# lpcb register map
Vendor: Texas Instruments
Peripheral module from a debugger description file (folder sc4e129bnczad).
Registers are 32-bit, read-write, no defined reset value unless marked. A register's access mark holds for its fields unless they carry their own. Offsets are as the file gives them; lines under a group give offsets from that group; [hi:lo] are bit positions; {n}, {i} and the like mark numbered series; 'fields as' and 'values as' point back to an identical list; <NAME> marks a mode.

## LPCB0 — LPCB register offsets
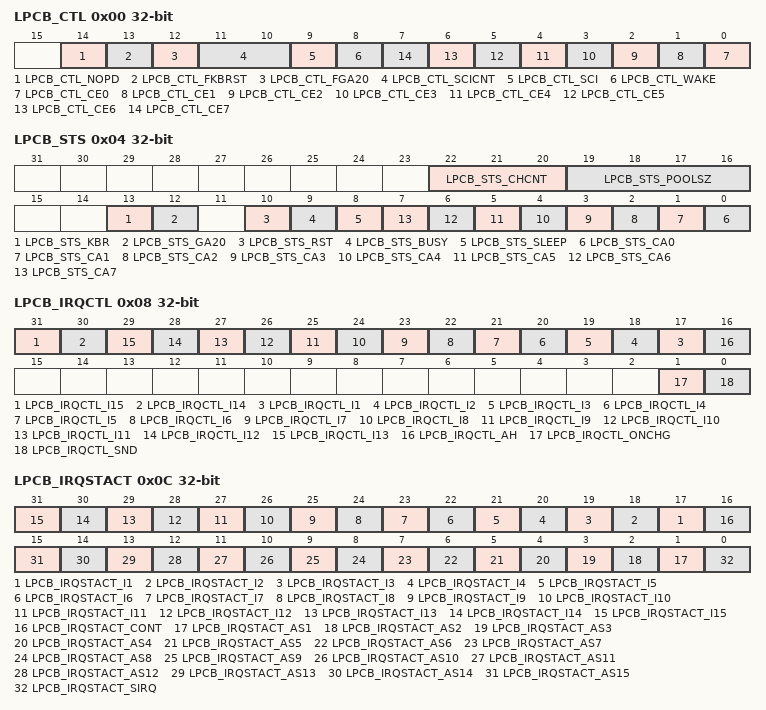
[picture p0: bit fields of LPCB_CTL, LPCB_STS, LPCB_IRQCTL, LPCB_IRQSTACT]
0x00 LPCB_CTL — LPCB Control
  [14] LPCB_CTL_NOPD — No Power Down Mode
  [13] LPCB_CTL_FKBRST — Fast Keyboard Reset Channel 0 Enable
  [12] LPCB_CTL_FGA20 — Fast Gate A-20 Channel 0 Enable
  [11:10] LPCB_CTL_SCICNT — LPC0SCI Pulse Length
    0=1-clock pulse; 1=2-clock pulse; 2=4-clock pulse; 3=8-clock pulse
  [9] LPCB_CTL_SCI — Start LPC0SCI Pulse
  [8] LPCB_CTL_WAKE — Wake or Keep Awake the LPC Bus
  [n] LPCB_CTL_CE{n} (n=0..7) — Enable Channel {n}
0x04 LPCB_STS ro — LPCB Status
  [22:20] LPCB_STS_CHCNT — Number of Channels
  [19:16] LPCB_STS_POOLSZ — Register Pool Size
    1=256 bytes; 2=512 bytes; 3=768 bytes; 4=1024 bytes; 5=1280 bytes; 6=1536 bytes; 7=1792 bytes; 8=2048 bytes
  [13] LPCB_STS_KBR — LPC Keyboard Reset Status
  [12] LPCB_STS_GA20 — Gate A20 Status
  [10] LPCB_STS_RST — LPC Bus is in Reset
  [9] LPCB_STS_BUSY — LPC is Busy
  [8] LPCB_STS_SLEEP — Sleep Mode
  [n] LPCB_STS_CA{n} (n=0..7) — Channel {n} Active
0x08 LPCB_IRQCTL — LPCB IRQ Control
  [31] LPCB_IRQCTL_I15 — Pulsed IRQ15 State
  [30] LPCB_IRQCTL_I14 — Pulsed IRQ14 State
  [n+16] LPCB_IRQCTL_I{n} (n=1..13) — Pulsed IIRQ{n} State
  [16] LPCB_IRQCTL_AH — Active High Control
  [1] LPCB_IRQCTL_ONCHG — Initiate on Change
  [0] LPCB_IRQCTL_SND — Initiate Immediately
0x0C LPCB_IRQSTACT — LPCB IRQ Status and Active State
  [n+16] LPCB_IRQSTACT_I{n} (n=1..15) — IRQ{n} State
  [16] LPCB_IRQSTACT_CONT — Continuous Mode Status
  [n] LPCB_IRQSTACT_AS{n} (n=1..15) — IRQ{n} Active State
  [0] LPCB_IRQSTACT_SIRQ — SERIRQ Transaction Frame Being Processed
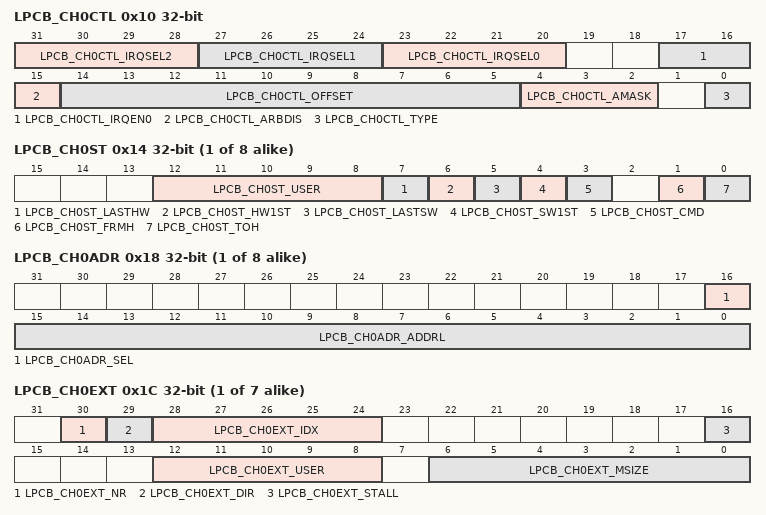
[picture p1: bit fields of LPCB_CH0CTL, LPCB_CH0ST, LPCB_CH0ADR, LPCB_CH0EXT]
0x10 LPCB_CH0CTL — LPCB Channel 0 Control
  [31:28] LPCB_CH0CTL_IRQSEL2 — IRQ Select 2
  [27:24] LPCB_CH0CTL_IRQSEL1 — IRQ Select 1
  [23:20] LPCB_CH0CTL_IRQSEL0 — IRQ Select 0
  [17:16] LPCB_CH0CTL_IRQEN0 — IRQ Enable 0
    0=LPCB_CH0CTL_IRQEN0_DIS (Trigger disabled); 1=LPCB_CH0CTL_IRQEN0_TRIG1 (Trigger 1); 2=LPCB_CH0CTL_IRQEN0_TRIG2 (Trigger 2); 3=LPCB_CH0CTL_IRQEN0_TRIG3 (Trigger 3)
  [15] LPCB_CH0CTL_ARBDIS — Arbitration Disabled
  [14:5] LPCB_CH0CTL_OFFSET — Base Offset in Register Pool
  [4:2] LPCB_CH0CTL_AMASK — Address Mask for Ranges
    0=4 bytes; 1=8 bytes; 2=16 bytes; 3=32 bytes; 4=64 bytes; 5=128 bytes; 6=256 bytes; 7=512 bytes
  [0] LPCB_CH0CTL_TYPE — Channel Type
{0x14+0x10*i} LPCB_CH{i}ST (i=0..7) — LPCB Channel {i} Status
  [12:8] LPCB_CH{i}ST_USER — User Data
  [7] LPCB_CH{i}ST_LASTHW — Last Host Write
  [6] LPCB_CH{i}ST_HW1ST — Host Wrote First
  [5] LPCB_CH{i}ST_LASTSW — Last Slave Write
  [4] LPCB_CH{i}ST_SW1ST — Slave Wrote First
  [3] LPCB_CH{i}ST_CMD — Command or Data
  [1] LPCB_CH{i}ST_FRMH — From-Host Transaction
  [0] LPCB_CH{i}ST_TOH — To-Host Transaction
{0x18+0x10*i} LPCB_CH{i}ADR (i=0..7) — LPCB Channel {i} Address
  [16] LPCB_CH{i}ADR_SEL — Upper Address Select
  [15:0] LPCB_CH{i}ADR_ADDRL — Lower Address Match
{0x1C+0x10*i} LPCB_CH{i}EXT (i=0..6) — LPCB Channel {i} Extension
  [30] LPCB_CH{i}EXT_NR — Not Ready Status
  [29] LPCB_CH{i}EXT_DIR — Mailbox Operation Direction
  [28:24] LPCB_CH{i}EXT_IDX — Mailbox Operation Index
  [16] LPCB_CH{i}EXT_STALL — Stall Mode Enable
  [12:8] LPCB_CH{i}EXT_USER — User Status
  [6:0] LPCB_CH{i}EXT_MSIZE — Mailbox Size
    0=LPCB_CH{i}EXT_MSIZE_FULL (Mailbox range is full size. MSIZE does not change mailbox range)
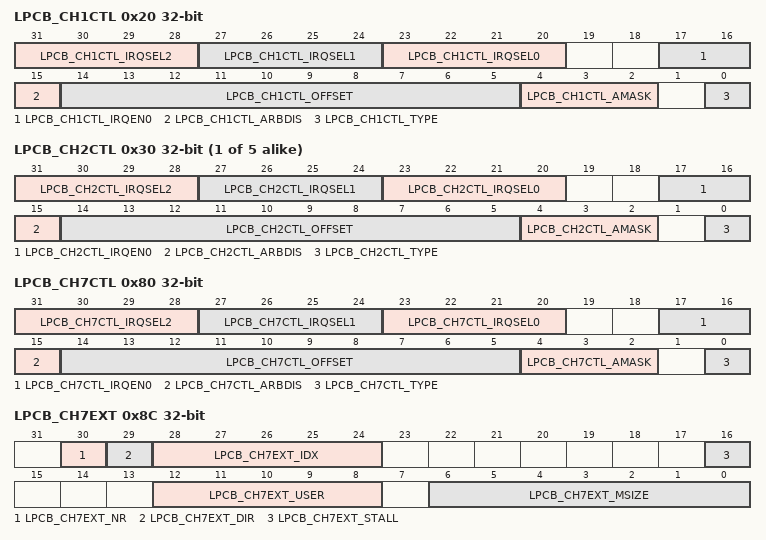
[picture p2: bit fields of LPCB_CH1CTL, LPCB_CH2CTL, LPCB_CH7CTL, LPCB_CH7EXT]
0x20 LPCB_CH1CTL — LPCB Channel 1 Control
  [31:28] LPCB_CH1CTL_IRQSEL2 — IRQ Select 2
  [27:24] LPCB_CH1CTL_IRQSEL1 — IRQ Select 1
  [23:20] LPCB_CH1CTL_IRQSEL0 — IRQ Select 0
  [17:16] LPCB_CH1CTL_IRQEN0 — IRQ Enable 0
    0=LPCB_CH1CTL_IRQEN0_DIS (Trigger disabled); 1=LPCB_CH1CTL_IRQEN0_TRIG1 (Trigger 1); 2=LPCB_CH1CTL_IRQEN0_TRGI2 (Trigger 2); 3=LPCB_CH1CTL_IRQEN0_TRGI3 (Trigger 3)
  [15] LPCB_CH1CTL_ARBDIS — Arbitration Disabled
  [14:5] LPCB_CH1CTL_OFFSET — Base Offset in Register Pool
  [4:2] LPCB_CH1CTL_AMASK — Address Mask for Ranges
    values as LPCB_CH0CTL.LPCB_CH0CTL_AMASK
  [0] LPCB_CH1CTL_TYPE — Channel Type
{0x10+0x10*i} LPCB_CH{i}CTL (i=2..6) — LPCB Channel {i} Control
  [31:28] LPCB_CH{i}CTL_IRQSEL2 — IRQ Select 2
  [27:24] LPCB_CH{i}CTL_IRQSEL1 — IRQ Select 1
  [23:20] LPCB_CH{i}CTL_IRQSEL0 — IRQ Select 0
  [17:16] LPCB_CH{i}CTL_IRQEN0 — IRQ Enable 0
    0=LPCB_CH{i}CTL_IRQEN0_DIS (Trigger disabled); 1=LPCB_CH{i}CTL_IRQEN0_TRIG1 (Trigger 1); 2=LPCB_CH{i}CTL_IRQEN0_TRIG2 (Trigger 2); 3=LPCB_CH{i}CTL_IRQEN0_TRIG3 (Trigger 3)
  [15] LPCB_CH{i}CTL_ARBDIS — Arbitration Disabled
  [14:5] LPCB_CH{i}CTL_OFFSET — Base Offset in Register Pool
  [4:2] LPCB_CH{i}CTL_AMASK — Address Mask for Ranges
    values as LPCB_CH0CTL.LPCB_CH0CTL_AMASK
  [0] LPCB_CH{i}CTL_TYPE — Channel Type
0x80 LPCB_CH7CTL — LPCB Channel 7 Control
  [31:28] LPCB_CH7CTL_IRQSEL2 — IRQ Select 2
  [27:24] LPCB_CH7CTL_IRQSEL1 — IRQ Select 1
  [23:20] LPCB_CH7CTL_IRQSEL0 — IRQ Select 0
  [17:16] LPCB_CH7CTL_IRQEN0 — IRQ Enable 0
    0=LPCB_CH7CTL_IRQEN0_AUTO (Trigger disabled); 1=LPCB_CH7CTL_IRQEN0_MST (Trigger 1); 2=LPCB_CH7CTL_IRQEN0_SLV (Trigger 2); 3=LPCB_CH7CTL_IRQEN0_TRIG3 (Trigger 3)
  [15] LPCB_CH7CTL_ARBDIS — Arbitration Disabled
  [14:5] LPCB_CH7CTL_OFFSET — Base Offset in Register Pool
  [4:2] LPCB_CH7CTL_AMASK — Address Mask for Ranges
    values as LPCB_CH0CTL.LPCB_CH0CTL_AMASK
  [0] LPCB_CH7CTL_TYPE — Channel Type
0x8C LPCB_CH7EXT — LPCB Channel 7 Extension
  [30] LPCB_CH7EXT_NR — Not Ready Status
  [29] LPCB_CH7EXT_DIR — Mailbox Operation Direction
  [28:24] LPCB_CH7EXT_IDX — Mailbox Operation Index
  [16] LPCB_CH7EXT_STALL — Stall Mode Enable
  [12:8] LPCB_CH7EXT_USER — User Status
  [6:0] LPCB_CH7EXT_MSIZE — Mailbox Size
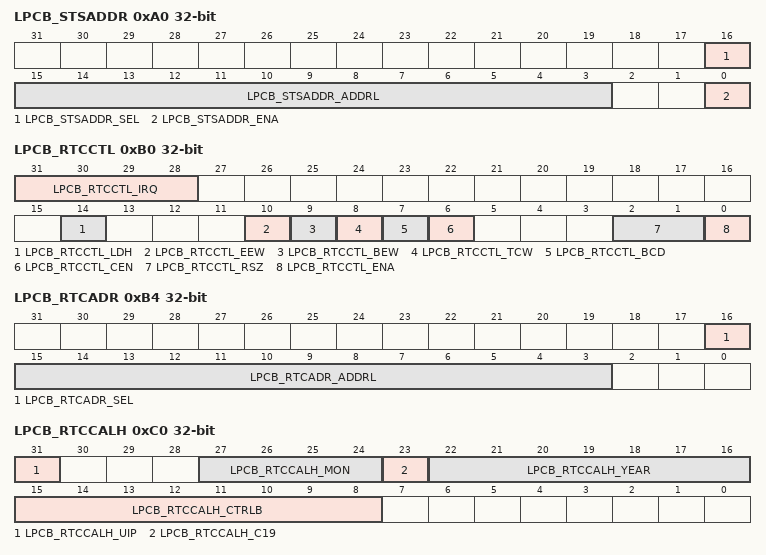
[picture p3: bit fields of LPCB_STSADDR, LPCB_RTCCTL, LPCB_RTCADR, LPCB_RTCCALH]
0xA0 LPCB_STSADDR — LPCB Status Block Address
  [16] LPCB_STSADDR_SEL — Upper Address Selector
  [15:3] LPCB_STSADDR_ADDRL — Lower Address Match
  [0] LPCB_STSADDR_ENA — Enable Status Block
0xB0 LPCB_RTCCTL — LPCB RTC Control
  [31:28] LPCB_RTCCTL_IRQ — IRQ Enable
  [14] LPCB_RTCCTL_LDH — Load Data
  [10] LPCB_RTCCTL_EEW — Extended Memory Write
  [9] LPCB_RTCCTL_BEW — Base Memory Write
  [8] LPCB_RTCCTL_TCW — TOD/Calendar Write
  [7] LPCB_RTCCTL_BCD — BCD Status
  [6] LPCB_RTCCTL_CEN — Century Enable
  [2:1] LPCB_RTCCTL_RSZ — RTC RAM Size
    0=64 bytes (50); 1=128 bytes (114); 2=256 bytes (242); 3=512 bytes (498)
  [0] LPCB_RTCCTL_ENA — RTC TOD/Calendar Enable
0xB4 LPCB_RTCADR — LPCB RTC Address
  [16] LPCB_RTCADR_SEL — Upper Address Selector
  [15:3] LPCB_RTCADR_ADDRL — Lower Address Match
0xC0 LPCB_RTCCALH — LPCB RTC Calendar High
  [31] LPCB_RTCCALH_UIP — Update in Progress
  [27:24] LPCB_RTCCALH_MON — Month Value
  [23] LPCB_RTCCALH_C19 — Century Value
  [22:16] LPCB_RTCCALH_YEAR — Year Value
  [15:8] LPCB_RTCCALH_CTRLB — CTRLB Value
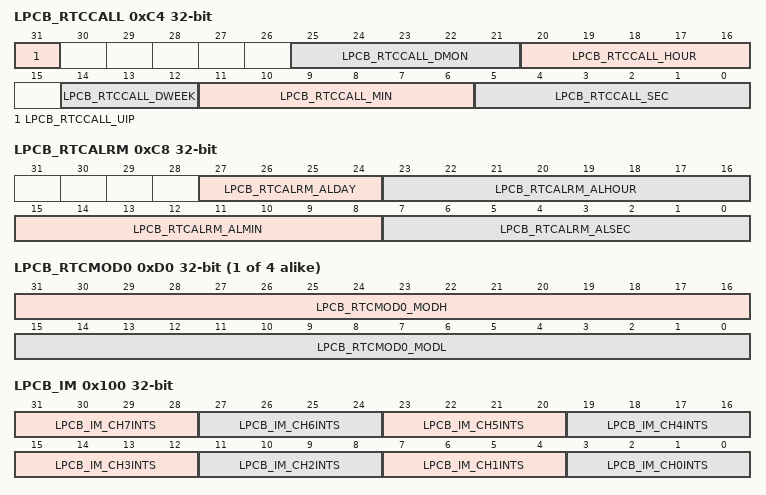
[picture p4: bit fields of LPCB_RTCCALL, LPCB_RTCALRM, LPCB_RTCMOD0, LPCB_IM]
0xC4 LPCB_RTCCALL — LPCB RTC Calendar Low
  [31] LPCB_RTCCALL_UIP — Update in Progress
  [25:21] LPCB_RTCCALL_DMON — Day-of-Month Value
  [20:16] LPCB_RTCCALL_HOUR — Hour Value
  [14:12] LPCB_RTCCALL_DWEEK — Day-of-Week Value
  [11:6] LPCB_RTCCALL_MIN — Minute Value
  [5:0] LPCB_RTCCALL_SEC — Seconds Value
0xC8 LPCB_RTCALRM — LPCB RTC Alarm
  [27:24] LPCB_RTCALRM_ALDAY — Hour Alarm
  [23:16] LPCB_RTCALRM_ALHOUR — Hour Alarm
  [15:8] LPCB_RTCALRM_ALMIN — Minute Alarm
  [7:0] LPCB_RTCALRM_ALSEC — Seconds Alarm
{0xD0+4i} LPCB_RTCMOD{i} (i=0..3) — LPCB RTC Modify {i} Register
  [31:16] LPCB_RTCMOD{i}_MODH — RTC Pool Upper Modification Status
  [15:0] LPCB_RTCMOD{i}_MODL — RTC Pool Lower Memory Modification Status
0x100 LPCB_IM — LPCB Interrupt Mask
  [31:28] LPCB_IM_CH7INTS — Channel 7 Interrupt Mask
    0=LPCB_IM_CH7INTS__0 (Stall); 1=LPCB_IM_CH7INTS__1 (Stall); 2=LPCB_IM_CH7INTS__2 (MB); 3=LPCB_IM_CH7INTS__3 (MB)
  [4n+3:4n] LPCB_IM_CH{n}INTS (n=0..6) — Channel {n} Interrupt Mask
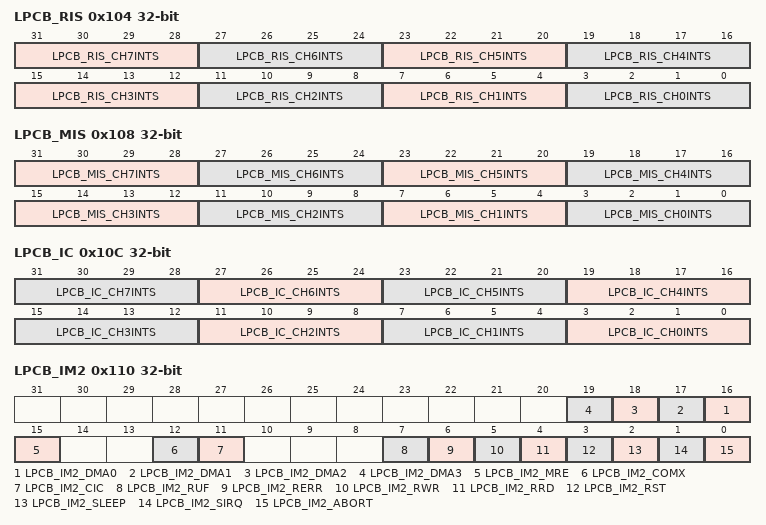
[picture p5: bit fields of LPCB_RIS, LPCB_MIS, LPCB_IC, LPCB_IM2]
0x104 LPCB_RIS ro — LPCB Raw Interrupt Status
  [31:28] LPCB_RIS_CH7INTS — Channel 7 Raw Interrupt Status
    0=LPCB_RIS_CH7INTS__0 (Stall); 1=LPCB_RIS_CH7INTS__1 (Stall); 2=LPCB_RIS_CH7INTS__2 (MB); 3=LPCB_RIS_CH7INTS__3 (MB)
  [4n+3:4n] LPCB_RIS_CH{n}INTS (n=0..6) — Channel {n} Raw Interrupt Status
0x108 LPCB_MIS ro — LPCB Masked Interrupt Status
  [31:28] LPCB_MIS_CH7INTS — Channel 7 Masked Interrupt Status
    0=LPCB_MIS_CH7INTS__0 (Stall); 1=LPCB_MIS_CH7INTS__1 (Stall); 2=LPCB_MIS_CH7INTS__2 (MB); 3=LPCB_MIS_CH7INTS__3 (MB)
  [4n+3:4n] LPCB_MIS_CH{n}INTS (n=0..6) — Channel {n} Masked Interrupt Status
0x10C LPCB_IC wo — LPCB Interrupt Clear
  [4n+3:4n] LPCB_IC_CH{n}INTS (n=0..7) — Channel {n} Interrupt Clear
0x110 LPCB_IM2 — LPCB Interrupt Mask 2
  [n+16] LPCB_IM2_DMA{n} (n=0..3) — DMA Done Channel {n} Interrupt Mask
  [15] LPCB_IM2_MRE — Memory Pool Retention Interrupt Mask
  [12] LPCB_IM2_COMX — COMx Interrupt Mask
  [11] LPCB_IM2_CIC — COMxy Intercept Interrupt Mask
  [7] LPCB_IM2_RUF — RTC Update Finish Interrupt Mask
  [6] LPCB_IM2_RERR — RTC Error Interrupt Mask
  [5] LPCB_IM2_RWR — RTC Write Interrupt Mask
  [4] LPCB_IM2_RRD — RTC Read Interrupt Mask
  [3] LPCB_IM2_RST — LPC Reset Interrupt Mask
  [2] LPCB_IM2_SLEEP — LPC Sleep Interrupt Mask
  [1] LPCB_IM2_SIRQ — SERIRQ Interrupt Mask
  [0] LPCB_IM2_ABORT — Abort Interrupt Mask
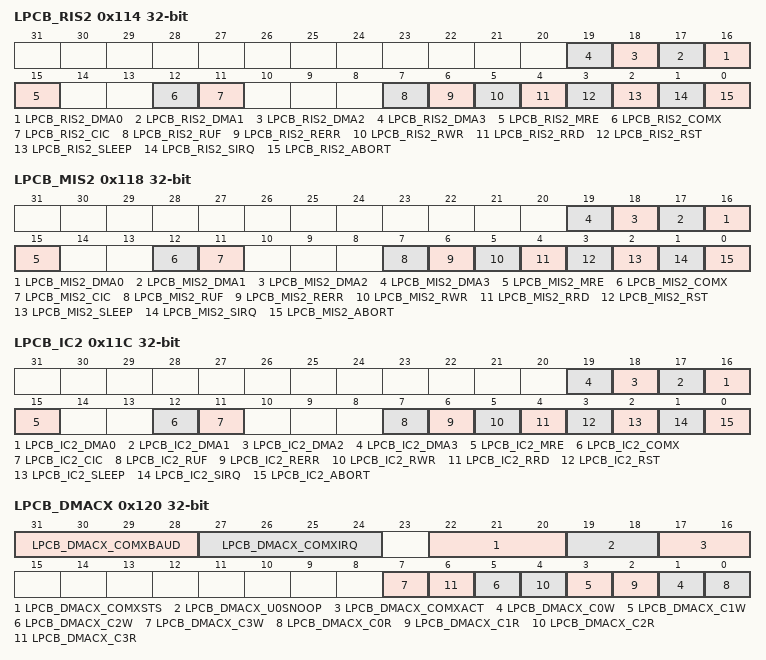
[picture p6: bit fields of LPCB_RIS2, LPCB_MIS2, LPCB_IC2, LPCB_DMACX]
0x114 LPCB_RIS2 — LPCB Raw Interrupt Status 2
  [n+16] LPCB_RIS2_DMA{n} (n=0..3) — DMA Done Channel {n} Raw Interrupt Status
  [15] LPCB_RIS2_MRE — Memory Pool Retention Raw Interrupt Status
  [12] LPCB_RIS2_COMX — COMx Raw Interrupt Status
  [11] LPCB_RIS2_CIC — COMxy Intercept Raw Interrupt Status
  [7] LPCB_RIS2_RUF — RTC Update Finish Raw Interrupt Status
  [6] LPCB_RIS2_RERR — RTC Error Raw Interrupt Status
  [5] LPCB_RIS2_RWR — RTC Write Raw Interrupt Status
  [4] LPCB_RIS2_RRD — RTC Read Raw Interrupt Status
  [3] LPCB_RIS2_RST — LPC Reset Raw Interrupt Status
  [2] LPCB_RIS2_SLEEP — LPC Sleep Raw Interrupt Status
  [1] LPCB_RIS2_SIRQ — SERIRQ Raw Interrupt Status
  [0] LPCB_RIS2_ABORT — Abort Raw Interrupt Status
0x118 LPCB_MIS2 — LPCB Masked Interrupt Status 2
  [n+16] LPCB_MIS2_DMA{n} (n=0..3) — DMA Done Channel {n} Masked Interrupt Status
  [15] LPCB_MIS2_MRE — Memory Pool Retention Masked Interrupt Status
  [12] LPCB_MIS2_COMX — COMx Masked Interrupt Status
  [11] LPCB_MIS2_CIC — COMxy Intercept Masked Interrupt Status
  [7] LPCB_MIS2_RUF — RTC Update Finish Masked Interrupt Status
  [6] LPCB_MIS2_RERR — RTC Error Masked Interrupt Status
  [5] LPCB_MIS2_RWR — RTC Write Masked Interrupt Status
  [4] LPCB_MIS2_RRD — RTC Read Masked Interrupt Status
  [3] LPCB_MIS2_RST — LPC Reset Masked Interrupt Status
  [2] LPCB_MIS2_SLEEP — LPC Sleep Masked Interrupt Status
  [1] LPCB_MIS2_SIRQ — SERIRQ Masked Interrupt Status
  [0] LPCB_MIS2_ABORT — Abort Masked Interrupt Status
0x11C LPCB_IC2 — LPCB Interrupt Clear 2
  [n+16] LPCB_IC2_DMA{n} (n=0..3) — Channel {n} DMA Done Interrupt Clear
  [15] LPCB_IC2_MRE — Memory Pool Retention Interrupt Clear
  [12] LPCB_IC2_COMX — COMx Interrupt Clear
  [11] LPCB_IC2_CIC — COMxy Intercept Mode Interrupt Clear
  [7] LPCB_IC2_RUF — RTC Update Finish Interrupt Clear
  [6] LPCB_IC2_RERR — RTC Error Interrupt Clear
  [5] LPCB_IC2_RWR — RTC Write Interrupt Clear
  [4] LPCB_IC2_RRD — RTC Read Interrupt Clear
  [3] LPCB_IC2_RST — LPC Reset Interrupt Clear
  [2] LPCB_IC2_SLEEP — LPC Sleep Interrupt Clear
  [1] LPCB_IC2_SIRQ — SERIRQ Interrupt Clear
  [0] LPCB_IC2_ABORT — Abort Interrupt Clear
0x120 LPCB_DMACX — LPCB DMA and COMx Control
  [31:28] LPCB_DMACX_COMXBAUD — COMx Baud Rate
    0=LPCB_DMACX_COMXBAUD_HOST (DLAB (host)); 1=9,600; 2=19,200; 3=38,400; 4=56,000; 5=115,200; 6=230,400; 7=460,800; 8=921,600; 9=1,250,000; 10=1,500,000; 11=2,500,000
  [27:24] LPCB_DMACX_COMXIRQ — COMx IRQ
  [22:20] LPCB_DMACX_COMXSTS — COMx Status
    0=LPCB_DMACX_COMXSTS_TOHOST (To-host reads have occurred); 1=LPCB_DMACX_COMXSTS_FROMHOST (From-host writes have occurred); 2=LPCB_DMACX_COMXSTS_ERROR (UART errors have occurred)
  [19:18] LPCB_DMACX_U0SNOOP — UART0 Snoop Enable
    0=LPCB_DMACX_U0SNOOP_NOSNOOP (No snoop); 1=LPCB_DMACX_U0SNOOP_SNPTX (Snoop 16550 TX); 2=LPCB_DMACX_U0SNOOP_SNPRX (Snoop 16550 RX)
  [17:16] LPCB_DMACX_COMXACT — COMx Configuration
    0=LPCB_DMACX_COMXACT_DIS (Disabled); 1=LPCB_DMACX_COMXACT_FLUSH (Ignore from-host bytes and continue to mark COMx TX status as empty. This tells the host the TX FIFO is not full, but just throws away data bytes from the host); 2=LPCB_DMACX_COMXACT_BLOCK (Blocked status. This marks the COMx TX status as full (FIFO full) holding the host off if it wants to send data bytes); 3=LPCB_DMACX_COMXACT_NORM (COMx model with 16550 UART as described in COMx channel support)
  [2n+1] LPCB_DMACX_C{n}W (n=0..3) — Channel {n} Write Control
  [2n] LPCB_DMACX_C{n}R (n=0..3) — Channel {n} Read Control
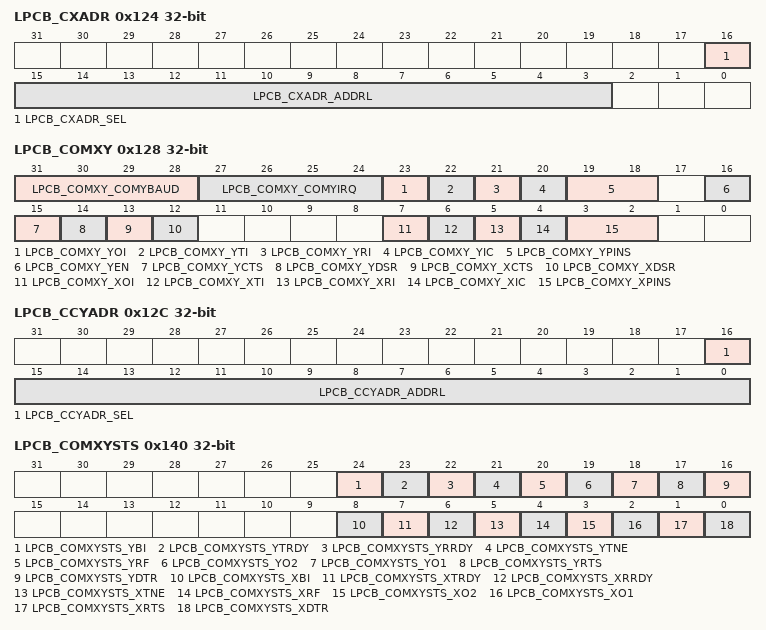
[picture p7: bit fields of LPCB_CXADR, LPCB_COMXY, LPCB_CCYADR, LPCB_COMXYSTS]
0x124 LPCB_CXADR — LPCB COMx Address
  [16] LPCB_CXADR_SEL — Upper Address Selector
  [15:3] LPCB_CXADR_ADDRL — Lower Address Match
0x128 LPCB_COMXY — LPCB COMx and COMy Extended Control
  [31:28] LPCB_COMXY_COMYBAUD — COMy Baud Rate
    0=LPCB_COMXY_COMYBAUD_DLAB (DLAB (host)); 1=9,600; 2=19,200; 3=38,400; 4=56,000; 5=115,200; 6=230,400; 7=460,800; 8=921,600; 9=1,250,000; 10=1,500,000; 11=2,500,000
  [27:24] LPCB_COMXY_COMYIRQ — COMy IRQ
  [23] LPCB_COMXY_YOI — COMy Modem Change Interrupt Mask
  [22] LPCB_COMXY_YTI — COMy Host TX FIFO Not Empty Interrupt Mask
  [21] LPCB_COMXY_YRI — COMy Host RX FIFO Full Interrupt Mask
  [20] LPCB_COMXY_YIC — COMy Intercept Mode
  [19:18] LPCB_COMXY_YPINS — UART Pin Select for COMy
    0=LPCB_COMXY_YPINS_2WIRE (Normal two-wire configuration (RX, TX)); 1=LPCB_COMXY_YPINS_4WIRE (Four-wire configuration (RX, TX, RTS, CTS))
  [16] LPCB_COMXY_YEN — COMy Enable
  [15] LPCB_COMXY_YCTS — CTS control
  [14] LPCB_COMXY_YDSR — DSR control
  [13] LPCB_COMXY_XCTS — CTS control
  [12] LPCB_COMXY_XDSR — DSR control
  [7] LPCB_COMXY_XOI — COMx Modem Change Interrupt Mask
  [6] LPCB_COMXY_XTI — COMx Host TX FIFO Not Empty Interrupt Mask
  [5] LPCB_COMXY_XRI — COMx Host RX FIFO Full Interrupt Mask
  [4] LPCB_COMXY_XIC — COMx Intercept Mode
  [3:2] LPCB_COMXY_XPINS — UART Pin Select for COMx
    0=LPCB_COMXY_XPINS_2WIRE (Normal two-wire configuration (RX, TX)); 1=LPCB_COMXY_XPINS_4WIRE (Four-wire configuration (RX, TX, RTS, CTS)); 2=LPCB_COMXY_XPINS_PMODEM (Partial Modem (RX, TX, RTS, CTS, DTR, DSR)); 3=LPCB_COMXY_XPINS_FMODEM (Full modem (RX, TX, RTS, CTS, DTR, DSR, DCD, RI))
0x12C LPCB_CCYADR — LPCB COMy Address
  [16] LPCB_CCYADR_SEL — Selector for Upper Address
  [15:0] LPCB_CCYADR_ADDRL — Lower Address
0x130 LPCB_BASE — LPCB Base Address
  [31:16] LPCB_BASE_ADDRH — Upper Address
0x140 LPCB_COMXYSTS ro — LPCB COMx and COMy Status
  [24] LPCB_COMXYSTS_YBI — Line Control Set Break Status
  [23] LPCB_COMXYSTS_YTRDY — COMy TX FIFO ready
  [22] LPCB_COMXYSTS_YRRDY — COMy RX FIFO ready
  [21] LPCB_COMXYSTS_YTNE — COMy Host TX FIFO Not Empty
  [20] LPCB_COMXYSTS_YRF — COMy Host RX FIFO Full
  [19] LPCB_COMXYSTS_YO2 — COMy OUT2 Bit Status
  [18] LPCB_COMXYSTS_YO1 — COMy OUT1 Bit Status
  [17] LPCB_COMXYSTS_YRTS — RTS Status
  [16] LPCB_COMXYSTS_YDTR — DTR Status
  [8] LPCB_COMXYSTS_XBI — Line Control Set Break Status
  [7] LPCB_COMXYSTS_XTRDY — COMx TX FIFO ready
  [6] LPCB_COMXYSTS_XRRDY — COMx RX FIFO ready
  [5] LPCB_COMXYSTS_XTNE — COMx Host TX FIFO Not Empty
  [4] LPCB_COMXYSTS_XRF — COMx Host RX FIFO Full
  [3] LPCB_COMXYSTS_XO2 — COMx OUT2 Bit Status
  [2] LPCB_COMXYSTS_XO1 — COMx OUT1 Bit Status
  [1] LPCB_COMXYSTS_XRTS — RTS Status
  [0] LPCB_COMXYSTS_XDTR — DTR Status
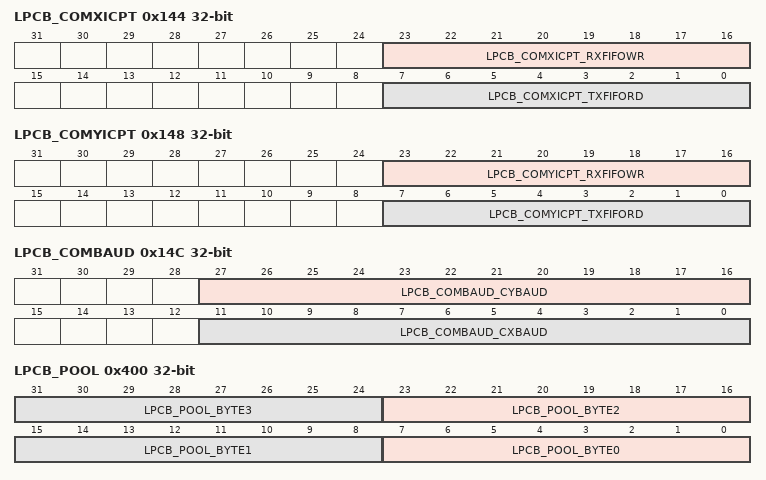
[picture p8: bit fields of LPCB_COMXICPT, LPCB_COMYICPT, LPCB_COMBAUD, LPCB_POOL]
0x144 LPCB_COMXICPT — LPCB COMx Intercept
  [23:16] LPCB_COMXICPT_RXFIFOWR — RXFIFO Write Data
  [7:0] LPCB_COMXICPT_TXFIFORD — TX FIFO Read Data
0x148 LPCB_COMYICPT — LPCB COMy Intercept
  [23:16] LPCB_COMYICPT_RXFIFOWR — RXFIFO Write Data
  [7:0] LPCB_COMYICPT_TXFIFORD — TX FIFO Read Data
0x14C LPCB_COMBAUD — LPCB COM Baud Override
  [27:16] LPCB_COMBAUD_CYBAUD — COMy baud count
  [11:0] LPCB_COMBAUD_CXBAUD — COMx baud count
0x400 LPCB_POOL — LPCB Register Pool
  [8n+7:8n] LPCB_POOL_BYTE{n} (n=0..3) — Byte {n}
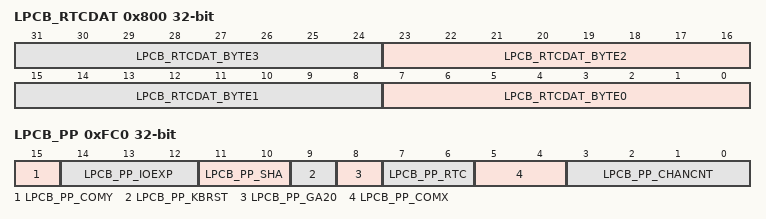
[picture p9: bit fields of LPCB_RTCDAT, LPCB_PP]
0x800 LPCB_RTCDAT — LPCB RTC Data
  [8n+7:8n] LPCB_RTCDAT_BYTE{n} (n=0..3) — Byte {n}
0xFC0 LPCB_PP ro — LPCB Peripheral Properties
  [15] LPCB_PP_COMY — COMy Support
  [14:12] LPCB_PP_IOEXP — IO Expander Support
    0=LPCB_PP_IOEXP_NONE (No IO Expander)
  [11:10] LPCB_PP_SHA — SHA Hashing Support
    0=LPCB_PP_SHA_NONE (No SHA support); 1=SHA-1; 2=LPCB_PP_SHA_1_256 (SHA-1 and SHA-256)
  [9] LPCB_PP_KBRST — KBRST Support
  [8] LPCB_PP_GA20 — Fast GateA20 Support Available
  [7:6] LPCB_PP_RTC — RTC Support
    0=LPCB_PP_RTC_NONE (No RTC); 1=LPCB_PP_RTC_NOAUTO (RTC with no auto-load and no auto-store of EEPROM or HIB); 2=LPCB_PP_RTC_AUTOHIB (RTC with auto load and auto-store to HIB, but not EEPROM); 3=LPCB_PP_RTC_AUTOHIBEE (RTC with load and auto-store to HIB and EEPROM)
  [5:4] LPCB_PP_COMX — COMx Support Available
    0=LPCB_PP_COMX_NONE (No COMx); 1=LPCB_PP_COMX_LEGACY (Legacy DMA style); 2=16550 UART support; 3=LPCB_PP_COMX_FULL16550 (Full Modem 16550)
  [3:0] LPCB_PP_CHANCNT — Number of Channels (Excluding COMx)
